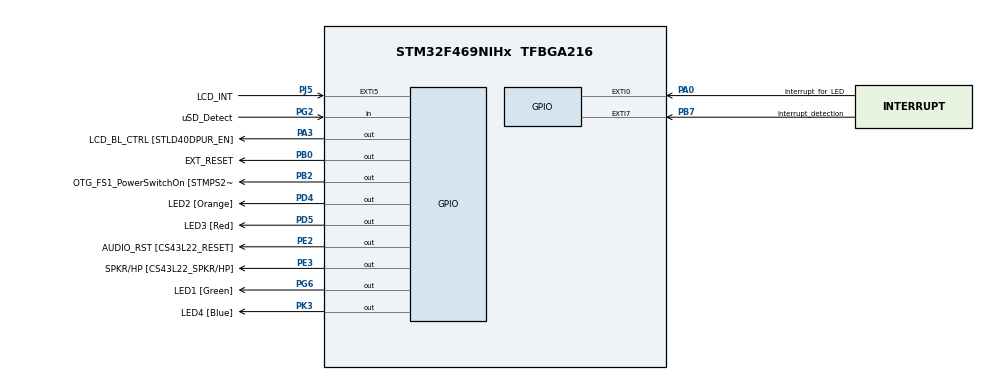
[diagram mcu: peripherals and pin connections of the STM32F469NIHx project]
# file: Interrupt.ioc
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DSIHOST_CKN.GPIO_Label=DSI_CK_N
DSIHOST_CKN.Signal=DSIHOST_CKN
DSIHOST_CKP.GPIO_Label=DSI_CK_P
DSIHOST_CKP.Signal=DSIHOST_CKP
DSIHOST_D0N.GPIO_Label=DSI_D0_N
DSIHOST_D0N.Signal=DSIHOST_D0N
DSIHOST_D0P.GPIO_Label=DSI_D0_P
DSIHOST_D0P.Signal=DSIHOST_D0P
DSIHOST_D1N.GPIO_Label=DSI_D1_N
DSIHOST_D1N.Signal=DSIHOST_D1N
DSIHOST_D1P.GPIO_Label=DSI_D1_P
DSIHOST_D1P.Signal=DSIHOST_D1P
Mcu.Family=STM32F4
Mcu.Name=STM32F469NIHx
Mcu.Package=TFBGA216
NVIC.EXTI0_IRQn=true\:1\:0\:true\:false\:true\:true\:true\:true
NVIC.EXTI9_5_IRQn=true\:0\:0\:false\:false\:true\:true\:true\:true
NVIC.PriorityGroup=NVIC_PRIORITYGROUP_4
PA0/WKUP.GPIO_Label=Interrupt_for_LED
PA0/WKUP.GPIO_ModeDefaultEXTI=GPIO_MODE_IT_FALLING
PA0/WKUP.Signal=GPXTI0
PA10.GPIO_Label=USB_FS1_ID
PA10.GPIO_Mode=GPIO_MODE_AF_PP
PA10.GPIO_PuPd=GPIO_NOPULL
PA10.GPIO_Speed=GPIO_SPEED_FREQ_VERY_HIGH
PA10.Signal=USB_OTG_FS_ID
PA11.GPIO_Label=USB_FS1_N
PA11.GPIO_Mode=GPIO_MODE_AF_PP
PA11.GPIO_PuPd=GPIO_NOPULL
PA11.GPIO_Speed=GPIO_SPEED_FREQ_VERY_HIGH
PA11.Signal=USB_OTG_FS_DM
PA12.GPIO_Label=USB_FS1_P
PA12.GPIO_Mode=GPIO_MODE_AF_PP
PA12.GPIO_PuPd=GPIO_NOPULL
PA12.GPIO_Speed=GPIO_SPEED_FREQ_VERY_HIGH
PA12.Signal=USB_OTG_FS_DP
PA13.GPIO_Label=SWDIO
PA13.Signal=SYS_JTMS-SWDIO
PA14.GPIO_Label=SWCLK
PA14.Signal=SYS_JTCK-SWCLK
PA3.GPIO_Label=LCD_BL_CTRL [STLD40DPUR_EN]
PA3.Signal=GPIO_Output
PA9.GPIO_Label=VBUS_FS1
PA9.GPIO_Mode=GPIO_MODE_AF_PP
PA9.GPIO_PuPd=GPIO_NOPULL
PA9.GPIO_Speed=GPIO_SPEED_FREQ_VERY_HIGH
PA9.Signal=USB_OTG_FS_VBUS
PB0.GPIO_Label=EXT_RESET
PB0.Signal=GPIO_Output
PB10.GPIO_Label=STLK_RX [STLINK V2-1_U2_RX]
PB10.Signal=USART3_TX
PB11.GPIO_Label=STLK_TX [STLINK V2-1_U2_TX]
PB11.Signal=USART3_RX
PB2/BOOT1.GPIO_Label=OTG_FS1_PowerSwitchOn [STMPS2151STR_En]
PB2/BOOT1.Signal=GPIO_Output
PB3.GPIO_Label=I2S3_CK
PB3.GPIO_Mode=GPIO_MODE_AF_PP
PB3.GPIO_PuPd=GPIO_NOPULL
PB3.GPIO_Speed=GPIO_SPEED_FREQ_LOW
PB3.Signal=I2S3_CK
PB6.GPIO_Label=QSPI_BK1_NCS [N25Q128A13EF840F_S]
PB6.GPIO_Mode=GPIO_MODE_AF_PP
PB6.GPIO_PuPd=GPIO_NOPULL
PB6.GPIO_Speed=GPIO_SPEED_FREQ_VERY_HIGH
PB6.Signal=QUADSPI_BK1_NCS
PB7.GPIO_Label=Interrupt_detection
PB7.GPIO_ModeDefaultEXTI=GPIO_MODE_IT_FALLING
PB7.GPIO_PuPd=GPIO_NOPULL
PB7.Signal=GPXTI7
PB8.GPIO_Label=I2C1_SCL
PB8.GPIO_Mode=GPIO_MODE_AF_OD
PB8.GPIO_PuPdOD=GPIO_PULLUP
PB8.GPIO_Speed=GPIO_SPEED_FREQ_VERY_HIGH
PB8.Signal=I2C1_SCL
PB9.GPIO_Label=I2C1_SDA
PB9.GPIO_Mode=GPIO_MODE_AF_OD
PB9.GPIO_PuPdOD=GPIO_PULLUP
PB9.GPIO_Speed=GPIO_SPEED_FREQ_VERY_HIGH
PB9.Signal=I2C1_SDA
PC0.GPIO_Label=SDNWE [MT48LC4M32B2B5-6A_WE]
PC0.Signal=FMC_SDNWE
PC10.GPIO_Label=uSD_D2
PC10.GPIO_Mode=GPIO_MODE_AF_PP
PC10.GPIO_PuPd=GPIO_NOPULL
PC10.GPIO_Speed_High_Default=GPIO_SPEED_FREQ_VERY_HIGH
PC10.Signal=SDIO_D2
PC11.GPIO_Label=uSD_D3
PC11.GPIO_Mode=GPIO_MODE_AF_PP
PC11.GPIO_PuPd=GPIO_NOPULL
PC11.GPIO_Speed_High_Default=GPIO_SPEED_FREQ_VERY_HIGH
PC11.Signal=SDIO_D3
PC12.GPIO_Label=uSD_CLK
PC12.GPIO_Mode=GPIO_MODE_AF_PP
PC12.GPIO_PuPd=GPIO_NOPULL
PC12.GPIO_Speed_High_Default=GPIO_SPEED_FREQ_VERY_HIGH
PC12.Signal=SDIO_CK
PC14/OSC32_IN.Signal=RCC_OSC32_IN
PC15/OSC32_OUT.Signal=RCC_OSC32_OUT
PC8.GPIO_Label=uSD_D0
PC8.GPIO_Mode=GPIO_MODE_AF_PP
PC8.GPIO_PuPd=GPIO_NOPULL
PC8.GPIO_Speed_High_Default=GPIO_SPEED_FREQ_VERY_HIGH
PC8.Signal=SDIO_D0
PC9.GPIO_Label=uSD_D1
PC9.GPIO_Mode=GPIO_MODE_AF_PP
PC9.GPIO_PuPd=GPIO_NOPULL
PC9.GPIO_Speed_High_Default=GPIO_SPEED_FREQ_VERY_HIGH
PC9.Signal=SDIO_D1
PD0.GPIO_Label=D2
PD0.GPIO_Mode=GPIO_MODE_AF_PP
PD0.GPIO_PuPd=GPIO_NOPULL
PD0.GPIO_Speed_High_Default=GPIO_SPEED_FREQ_VERY_HIGH
PD0.Signal=FMC_D2_DA2
PD1.GPIO_Label=D3
PD1.GPIO_Mode=GPIO_MODE_AF_PP
PD1.GPIO_PuPd=GPIO_NOPULL
PD1.GPIO_Speed_High_Default=GPIO_SPEED_FREQ_VERY_HIGH
PD1.Signal=FMC_D3_DA3
PD10.GPIO_Label=D15
PD10.Signal=FMC_D15_DA15
PD13.GPIO_Label=MIC_CK [MP34DT01TR_CLK]
PD13.Signal=S_TIM4_CH2
PD14.GPIO_Label=D0
PD14.Signal=FMC_D0_DA0
PD15.GPIO_Label=D1
PD15.Signal=FMC_D1_DA1
PD2.GPIO_Label=uSD_CMD
PD2.GPIO_Mode=GPIO_MODE_AF_PP
PD2.GPIO_PuPd=GPIO_NOPULL
PD2.GPIO_Speed_High_Default=GPIO_SPEED_FREQ_VERY_HIGH
PD2.Signal=SDIO_CMD
PD4.GPIO_Label=LED2 [Orange]
PD4.GPIO_ModeDefaultOutputPP=GPIO_MODE_OUTPUT_OD
PD4.GPIO_PuPd=GPIO_NOPULL
PD4.GPIO_Speed=GPIO_SPEED_FREQ_LOW
PD4.Signal=GPIO_Output
PD5.GPIO_Label=LED3 [Red]
PD5.GPIO_ModeDefaultOutputPP=GPIO_MODE_OUTPUT_OD
PD5.GPIO_PuPd=GPIO_NOPULL
PD5.GPIO_Speed=GPIO_SPEED_FREQ_LOW
PD5.Signal=GPIO_Output
PD6.GPIO_Label=MIC_DATA [MP34DT01TR_DOUT]
PD6.GPIO_Mode=GPIO_MODE_AF_PP
PD6.GPIO_PuPd=GPIO_NOPULL
PD6.GPIO_Speed=GPIO_SPEED_FREQ_LOW
PD6.Signal=SAI1_SD_A
PD8.GPIO_Label=D13
PD8.Signal=FMC_D13_DA13
PD9.GPIO_Label=D14
PD9.Signal=FMC_D14_DA14
PE0.GPIO_Label=FMC_NBL0 [ MT48LC4M32B2B5-6A_DQM0]
PE0.GPIO_Mode=GPIO_MODE_AF_PP
PE0.GPIO_PuPd=GPIO_NOPULL
PE0.GPIO_Speed_High_Default=GPIO_SPEED_FREQ_VERY_HIGH
PE0.Signal=FMC_NBL0
PE1.GPIO_Label=FMC_NBL1 [ MT48LC4M32B2B5-6A_DQM1]
PE1.GPIO_Mode=GPIO_MODE_AF_PP
PE1.GPIO_PuPd=GPIO_NOPULL
PE1.GPIO_Speed_High_Default=GPIO_SPEED_FREQ_VERY_HIGH
PE1.Signal=FMC_NBL1
PE10.GPIO_Label=D7
PE10.Signal=FMC_D7_DA7
PE11.GPIO_Label=D8
PE11.Signal=FMC_D8_DA8
PE12.GPIO_Label=D9
PE12.Signal=FMC_D9_DA9
PE13.GPIO_Label=D10
PE13.Signal=FMC_D10_DA10
PE14.GPIO_Label=D11
PE14.Signal=FMC_D11_DA11
PE15.GPIO_Label=D12
PE15.Signal=FMC_D12_DA12
PE2.GPIO_Label=AUDIO_RST [CS43L22_RESET]
PE2.GPIO_ModeDefaultOutputPP=GPIO_MODE_OUTPUT_PP
PE2.GPIO_PuPd=GPIO_NOPULL
PE2.GPIO_Speed=GPIO_SPEED_FREQ_LOW
PE2.Signal=GPIO_Output
PE3.GPIO_Label=SPKR/HP [CS43L22_SPKR/HP]
PE3.GPIO_ModeDefaultOutputPP=GPIO_MODE_OUTPUT_PP
PE3.GPIO_PuPd=GPIO_NOPULL
PE3.GPIO_Speed=GPIO_SPEED_FREQ_LOW
PE3.Signal=GPIO_Output
PE4.GPIO_Label=SAI1_FSA [CS43L22_LRCK]
PE4.GPIO_Mode=GPIO_MODE_AF_PP
PE4.GPIO_PuPd=GPIO_NOPULL
PE4.GPIO_Speed=GPIO_SPEED_FREQ_LOW
PE4.Signal=SAI1_FS_A
PE5.GPIO_Label=SAI1_SCKA [CS43L22_CLK]
PE5.GPIO_Mode=GPIO_MODE_AF_PP
PE5.GPIO_PuPd=GPIO_NOPULL
PE5.GPIO_Speed=GPIO_SPEED_FREQ_LOW
PE5.Signal=SAI1_SCK_A
PE7.GPIO_Label=D4
PE7.Signal=FMC_D4_DA4
PE8.GPIO_Label=D5
PE8.Signal=FMC_D5_DA5
PE9.GPIO_Label=D6
PE9.Signal=FMC_D6_DA6
PF0.GPIO_Label=A0
PF0.GPIO_Mode=GPIO_MODE_AF_PP
PF0.GPIO_PuPd=GPIO_NOPULL
PF0.GPIO_Speed_High_Default=GPIO_SPEED_FREQ_VERY_HIGH
PF0.Signal=FMC_A0
PF1.GPIO_Label=A1
PF1.GPIO_Mode=GPIO_MODE_AF_PP
PF1.GPIO_PuPd=GPIO_NOPULL
PF1.GPIO_Speed_High_Default=GPIO_SPEED_FREQ_VERY_HIGH
PF1.Signal=FMC_A1
PF10.GPIO_Label=QSPI_CLK [N25Q128A13EF840F_C]
PF10.Signal=QUADSPI_CLK
PF11.GPIO_Label=SDNMT48LC4M32B2B5-6A_RAS]RAS [
PF11.Signal=FMC_SDNRAS
PF12.GPIO_Label=A6
PF12.Signal=FMC_A6
PF13.GPIO_Label=A7
PF13.Signal=FMC_A7
PF14.GPIO_Label=A8
PF14.Signal=FMC_A8
PF15.GPIO_Label=A9
PF15.Signal=FMC_A9
PF2.GPIO_Label=A2
PF2.GPIO_Mode=GPIO_MODE_AF_PP
PF2.GPIO_PuPd=GPIO_NOPULL
PF2.GPIO_Speed_High_Default=GPIO_SPEED_FREQ_VERY_HIGH
PF2.Signal=FMC_A2
PF3.GPIO_Label=A3
PF3.GPIO_Mode=GPIO_MODE_AF_PP
PF3.GPIO_PuPd=GPIO_NOPULL
PF3.GPIO_Speed_High_Default=GPIO_SPEED_FREQ_VERY_HIGH
PF3.Signal=FMC_A3
PF4.GPIO_Label=A4
PF4.GPIO_Mode=GPIO_MODE_AF_PP
PF4.GPIO_PuPd=GPIO_NOPULL
PF4.GPIO_Speed_High_Default=GPIO_SPEED_FREQ_VERY_HIGH
PF4.Signal=FMC_A4
PF5.GPIO_Label=A5
PF5.Signal=FMC_A5
PF6.GPIO_Label=QSPI_BK1_IO3 [N25Q128A13EF840F_DQ3]
PF6.Signal=QUADSPI_BK1_IO3
PF7.GPIO_Label=QSPI_BK1_IO2 [N25Q128A13EF840F_DQ2]
PF7.Signal=QUADSPI_BK1_IO2
PF8.GPIO_Label=QSPI_BK1_IO0 [N25Q128A13EF840F_DQ0]
PF8.Signal=QUADSPI_BK1_IO0
PF9.GPIO_Label=QSPI_BK1_IO1 [N25Q128A13EF840F_DQ1]
PF9.Signal=QUADSPI_BK1_IO1
PG0.GPIO_Label=A10
PG0.Signal=FMC_A10
PG1.GPIO_Label=A11
PG1.Signal=FMC_A11
PG14.GPIO_Label=ARDUINO USART6_TX
PG14.GPIO_Mode=GPIO_MODE_AF_PP
PG14.GPIO_PuPd=GPIO_NOPULL
PG14.GPIO_Speed=GPIO_SPEED_FREQ_VERY_HIGH
PG14.Signal=USART6_TX
PG15.GPIO_Label=SDNCAS [MT48LC4M32B2B5-6A_CAS]
PG15.GPIO_Mode=GPIO_MODE_AF_PP
PG15.GPIO_PuPd=GPIO_NOPULL
PG15.GPIO_Speed_High_Default=GPIO_SPEED_FREQ_VERY_HIGH
PG15.Signal=FMC_SDNCAS
PG2.GPIO_Label=uSD_Detect
PG2.Signal=GPIO_Input
PG4.Signal=FMC_A14_BA0
PG5.Signal=FMC_A15_BA1
PG6.GPIO_Label=LED1 [Green]
PG6.GPIO_ModeDefaultOutputPP=GPIO_MODE_OUTPUT_OD
PG6.GPIO_PuPd=GPIO_NOPULL
PG6.GPIO_Speed=GPIO_SPEED_FREQ_LOW
PG6.Signal=GPIO_Output
PG7.GPIO_Label=SAI1_MCLKA [CS43L22_MCLK]
PG7.GPIO_Mode=GPIO_MODE_AF_PP
PG7.GPIO_PuPd=GPIO_NOPULL
PG7.GPIO_Speed=GPIO_SPEED_FREQ_LOW
PG7.Signal=SAI1_MCLK_A
PG8.GPIO_Label=SDCLK [MT48LC4M32B2B5-6A_CLK]
PG8.GPIO_Mode=GPIO_MODE_AF_PP
PG8.GPIO_PuPd=GPIO_NOPULL
PG8.GPIO_Speed_High_Default=GPIO_SPEED_FREQ_VERY_HIGH
PG8.Signal=FMC_SDCLK
PG9.GPIO_Label=USART6_RX
PG9.GPIO_Mode=GPIO_MODE_AF_PP
PG9.GPIO_PuPd=GPIO_NOPULL
PG9.GPIO_Speed=GPIO_SPEED_FREQ_VERY_HIGH
PG9.Signal=USART6_RX
PH0/OSC_IN.Signal=RCC_OSC_IN
PH1/OSC_OUT.Signal=RCC_OSC_OUT
PH10.GPIO_Label=D18
PH10.Signal=FMC_D18
PH11.GPIO_Label=D19
PH11.Signal=FMC_D19
PH12.GPIO_Label=D20
PH12.Signal=FMC_D20
PH13.GPIO_Label=D21
PH13.GPIO_Mode=GPIO_MODE_AF_PP
PH13.GPIO_PuPd=GPIO_NOPULL
PH13.GPIO_Speed_High_Default=GPIO_SPEED_FREQ_VERY_HIGH
PH13.Signal=FMC_D21
PH14.GPIO_Label=D22
PH14.GPIO_Mode=GPIO_MODE_AF_PP
PH14.GPIO_PuPd=GPIO_NOPULL
PH14.GPIO_Speed_High_Default=GPIO_SPEED_FREQ_VERY_HIGH
PH14.Signal=FMC_D22
PH15.GPIO_Label=D23
PH15.GPIO_Mode=GPIO_MODE_AF_PP
PH15.GPIO_PuPd=GPIO_NOPULL
PH15.GPIO_Speed_High_Default=GPIO_SPEED_FREQ_VERY_HIGH
PH15.Signal=FMC_D23
PH2.GPIO_Label=SDCKE0 [MT48LC4M32B2B5-6A_CKE]
PH2.Signal=FMC_SDCKE0
PH3.GPIO_Label=SDNE0 [MT48LC4M32B2B5-6A_CS]
PH3.GPIO_Mode=GPIO_MODE_AF_PP
PH3.GPIO_PuPd=GPIO_NOPULL
PH3.GPIO_Speed_High_Default=GPIO_SPEED_FREQ_VERY_HIGH
PH3.Signal=FMC_SDNE0
PH4.GPIO_Label=I2C2_SCL [CS43L22_SCL]
PH4.GPIO_Mode=GPIO_MODE_AF_OD
PH4.GPIO_PuPdOD=GPIO_PULLUP
PH4.GPIO_Speed=GPIO_SPEED_FREQ_VERY_HIGH
PH4.Signal=I2C2_SCL
PH5.GPIO_Label=I2C2_SDA [CS43L22_SDA]
PH5.GPIO_Mode=GPIO_MODE_AF_OD
PH5.GPIO_PuPdOD=GPIO_PULLUP
PH5.GPIO_Speed=GPIO_SPEED_FREQ_VERY_HIGH
PH5.Signal=I2C2_SDA
PH8.GPIO_Label=D16
PH8.Signal=FMC_D16
PH9.GPIO_Label=D17
PH9.Signal=FMC_D17
PI0.GPIO_Label=D24
PI0.GPIO_Mode=GPIO_MODE_AF_PP
PI0.GPIO_PuPd=GPIO_NOPULL
PI0.GPIO_Speed_High_Default=GPIO_SPEED_FREQ_VERY_HIGH
PI0.Signal=FMC_D24
PI1.GPIO_Label=D25
PI1.GPIO_Mode=GPIO_MODE_AF_PP
PI1.GPIO_PuPd=GPIO_NOPULL
PI1.GPIO_Speed_High_Default=GPIO_SPEED_FREQ_VERY_HIGH
PI1.Signal=FMC_D25
PI10.GPIO_Label=D31
PI10.GPIO_Mode=GPIO_MODE_AF_PP
PI10.GPIO_PuPd=GPIO_NOPULL
PI10.GPIO_Speed_High_Default=GPIO_SPEED_FREQ_VERY_HIGH
PI10.Signal=FMC_D31
PI2.GPIO_Label=D26
PI2.GPIO_Mode=GPIO_MODE_AF_PP
PI2.GPIO_PuPd=GPIO_NOPULL
PI2.GPIO_Speed_High_Default=GPIO_SPEED_FREQ_VERY_HIGH
PI2.Signal=FMC_D26
PI3.GPIO_Label=D27
PI3.GPIO_Mode=GPIO_MODE_AF_PP
PI3.GPIO_PuPd=GPIO_NOPULL
PI3.GPIO_Speed_High_Default=GPIO_SPEED_FREQ_VERY_HIGH
PI3.Signal=FMC_D27
PI4.GPIO_Label=FMC_NBL2 [MT48LC4M32B2B5-6A_DQM2]
PI4.GPIO_Mode=GPIO_MODE_AF_PP
PI4.GPIO_PuPd=GPIO_NOPULL
PI4.GPIO_Speed_High_Default=GPIO_SPEED_FREQ_VERY_HIGH
PI4.Signal=FMC_NBL2
PI5.GPIO_Label=FMC_NBL3 [MT48LC4M32B2B5-6A_DQM3]
PI5.GPIO_Mode=GPIO_MODE_AF_PP
PI5.GPIO_PuPd=GPIO_NOPULL
PI5.GPIO_Speed_High_Default=GPIO_SPEED_FREQ_VERY_HIGH
PI5.Signal=FMC_NBL3
PI6.GPIO_Label=D28
PI6.GPIO_Mode=GPIO_MODE_AF_PP
PI6.GPIO_PuPd=GPIO_NOPULL
PI6.GPIO_Speed_High_Default=GPIO_SPEED_FREQ_VERY_HIGH
PI6.Signal=FMC_D28
PI7.GPIO_Label=D29
PI7.GPIO_Mode=GPIO_MODE_AF_PP
PI7.GPIO_PuPd=GPIO_NOPULL
PI7.GPIO_Speed_High_Default=GPIO_SPEED_FREQ_VERY_HIGH
PI7.Signal=FMC_D29
PI9.GPIO_Label=D30
PI9.GPIO_Mode=GPIO_MODE_AF_PP
PI9.GPIO_PuPd=GPIO_NOPULL
PI9.GPIO_Speed_High_Default=GPIO_SPEED_FREQ_VERY_HIGH
PI9.Signal=FMC_D30
PJ2.GPIO_Label=DSI_TE
PJ2.Signal=DSIHOST_TE
PJ5.GPIO_Label=LCD_INT
PJ5.Signal=GPXTI5
PK3.GPIO_Label=LED4 [Blue]
PK3.GPIO_ModeDefaultOutputPP=GPIO_MODE_OUTPUT_OD
PK3.GPIO_PuPd=GPIO_NOPULL
PK3.GPIO_Speed=GPIO_SPEED_FREQ_LOW
PK3.Signal=GPIO_Output
ProjectManager.HeapSize=0x200
ProjectManager.StackSize=0x400
ProjectManager.TargetToolchain=STM32CubeIDE
RCC.CortexFreq_Value=16000000
RCC.VCOOutputFreq_Value=192000000
SH.FMC_A0.0=FMC_A0
SH.FMC_A1.0=FMC_A1
SH.FMC_A10.0=FMC_A10
SH.FMC_A11.0=FMC_A11
SH.FMC_A14_BA0.0=FMC_BA0
SH.FMC_A15_BA1.0=FMC_BA1
SH.FMC_A2.0=FMC_A2
SH.FMC_A3.0=FMC_A3
SH.FMC_A4.0=FMC_A4
SH.FMC_A5.0=FMC_A5
SH.FMC_A6.0=FMC_A6
SH.FMC_A7.0=FMC_A7
SH.FMC_A8.0=FMC_A8
SH.FMC_A9.0=FMC_A9
SH.FMC_D0_DA0.0=FMC_D0
SH.FMC_D10_DA10.0=FMC_D10
SH.FMC_D11_DA11.0=FMC_D11
SH.FMC_D12_DA12.0=FMC_D12
SH.FMC_D13_DA13.0=FMC_D13
SH.FMC_D14_DA14.0=FMC_D14
SH.FMC_D15_DA15.0=FMC_D15
SH.FMC_D16.0=FMC_D16
SH.FMC_D17.0=FMC_D17
SH.FMC_D18.0=FMC_D18
SH.FMC_D19.0=FMC_D19
SH.FMC_D1_DA1.0=FMC_D1
SH.FMC_D20.0=FMC_D20
SH.FMC_D21.0=FMC_D21
SH.FMC_D22.0=FMC_D22
SH.FMC_D23.0=FMC_D23
SH.FMC_D24.0=FMC_D24
SH.FMC_D25.0=FMC_D25
SH.FMC_D26.0=FMC_D26
SH.FMC_D27.0=FMC_D27
SH.FMC_D28.0=FMC_D28
SH.FMC_D29.0=FMC_D29
SH.FMC_D2_DA2.0=FMC_D2
SH.FMC_D30.0=FMC_D30
SH.FMC_D31.0=FMC_D31
SH.FMC_D3_DA3.0=FMC_D3
SH.FMC_D4_DA4.0=FMC_D4
SH.FMC_D5_DA5.0=FMC_D5
SH.FMC_D6_DA6.0=FMC_D6
SH.FMC_D7_DA7.0=FMC_D7
SH.FMC_D8_DA8.0=FMC_D8
SH.FMC_D9_DA9.0=FMC_D9
SH.FMC_NBL0.0=FMC_NBL0
SH.FMC_NBL1.0=FMC_NBL1
SH.FMC_NBL2.0=FMC_NBL2
SH.FMC_NBL3.0=FMC_NBL3
SH.FMC_SDCLK.0=FMC_SDCLK
SH.FMC_SDNCAS.0=FMC_SDNCAS
SH.FMC_SDNRAS.0=FMC_SDNRAS
SH.FMC_SDNWE.0=FMC_SDNWE
SH.S_TIM4_CH2.0=TIM4_CH2
board=STM32F469I-DISCO

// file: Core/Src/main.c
/* USER CODE BEGIN Header */
/**
  ******************************************************************************
  * @file           : main.c
  * @brief          : Main program body
  ******************************************************************************
  * @attention
  *
  * Copyright (c) 2022 STMicroelectronics.
  * All rights reserved.
  *
  * This software is licensed under terms that can be found in the LICENSE file
  * in the root directory of this software component.
  * If no LICENSE file comes with this software, it is provided AS-IS.
  *
  ******************************************************************************
  */
/* USER CODE END Header */
#include "main.h"
#include "gpio.h"

/* USER CODE BEGIN PV */

uint16_t tDelay = 50;

/* USER CODE END PV */

void SystemClock_Config(void);

int main(void)
{

  /* MCU Configuration--------------------------------------------------------*/

  /* Reset of all peripherals, Initializes the Flash interface and the Systick. */
  HAL_Init();

  /* Configure the system clock */
  SystemClock_Config();

  /* Initialize all configured peripherals */
  MX_GPIO_Init();

  /* Infinite loop */
  while (1)
  {

    /* USER CODE BEGIN 3 */
	  HAL_GPIO_TogglePin(LED1_GPIO_Port, LED1_Pin); //15
	  HAL_Delay(tDelay); //delay 50
  }
  /* USER CODE END 3 */
}

void SystemClock_Config(void)
{
  RCC_OscInitTypeDef RCC_OscInitStruct = {0};
  RCC_ClkInitTypeDef RCC_ClkInitStruct = {0};

  /** Configure the main internal regulator output voltage
  */
  __HAL_RCC_PWR_CLK_ENABLE();
  __HAL_PWR_VOLTAGESCALING_CONFIG(PWR_REGULATOR_VOLTAGE_SCALE3);

  /** Initializes the RCC Oscillators according to the specified parameters
  * in the RCC_OscInitTypeDef structure.
  */
  RCC_OscInitStruct.OscillatorType = RCC_OSCILLATORTYPE_HSI;
  RCC_OscInitStruct.HSIState = RCC_HSI_ON;
  RCC_OscInitStruct.HSICalibrationValue = RCC_HSICALIBRATION_DEFAULT;
  RCC_OscInitStruct.PLL.PLLState = RCC_PLL_NONE;
  if (HAL_RCC_OscConfig(&RCC_OscInitStruct) != HAL_OK)
  {
    Error_Handler();
  }

  /** Initializes the CPU, AHB and APB buses clocks
  */
  RCC_ClkInitStruct.ClockType = RCC_CLOCKTYPE_HCLK|RCC_CLOCKTYPE_SYSCLK
                              |RCC_CLOCKTYPE_PCLK1|RCC_CLOCKTYPE_PCLK2;
  RCC_ClkInitStruct.SYSCLKSource = RCC_SYSCLKSOURCE_HSI;
  RCC_ClkInitStruct.AHBCLKDivider = RCC_SYSCLK_DIV1;
  RCC_ClkInitStruct.APB1CLKDivider = RCC_HCLK_DIV1;
  RCC_ClkInitStruct.APB2CLKDivider = RCC_HCLK_DIV1;

  if (HAL_RCC_ClockConfig(&RCC_ClkInitStruct, FLASH_LATENCY_0) != HAL_OK)
  {
    Error_Handler();
  }
}

void Error_Handler(void)
{
  __disable_irq();
  while (1)
  {
  }
}
